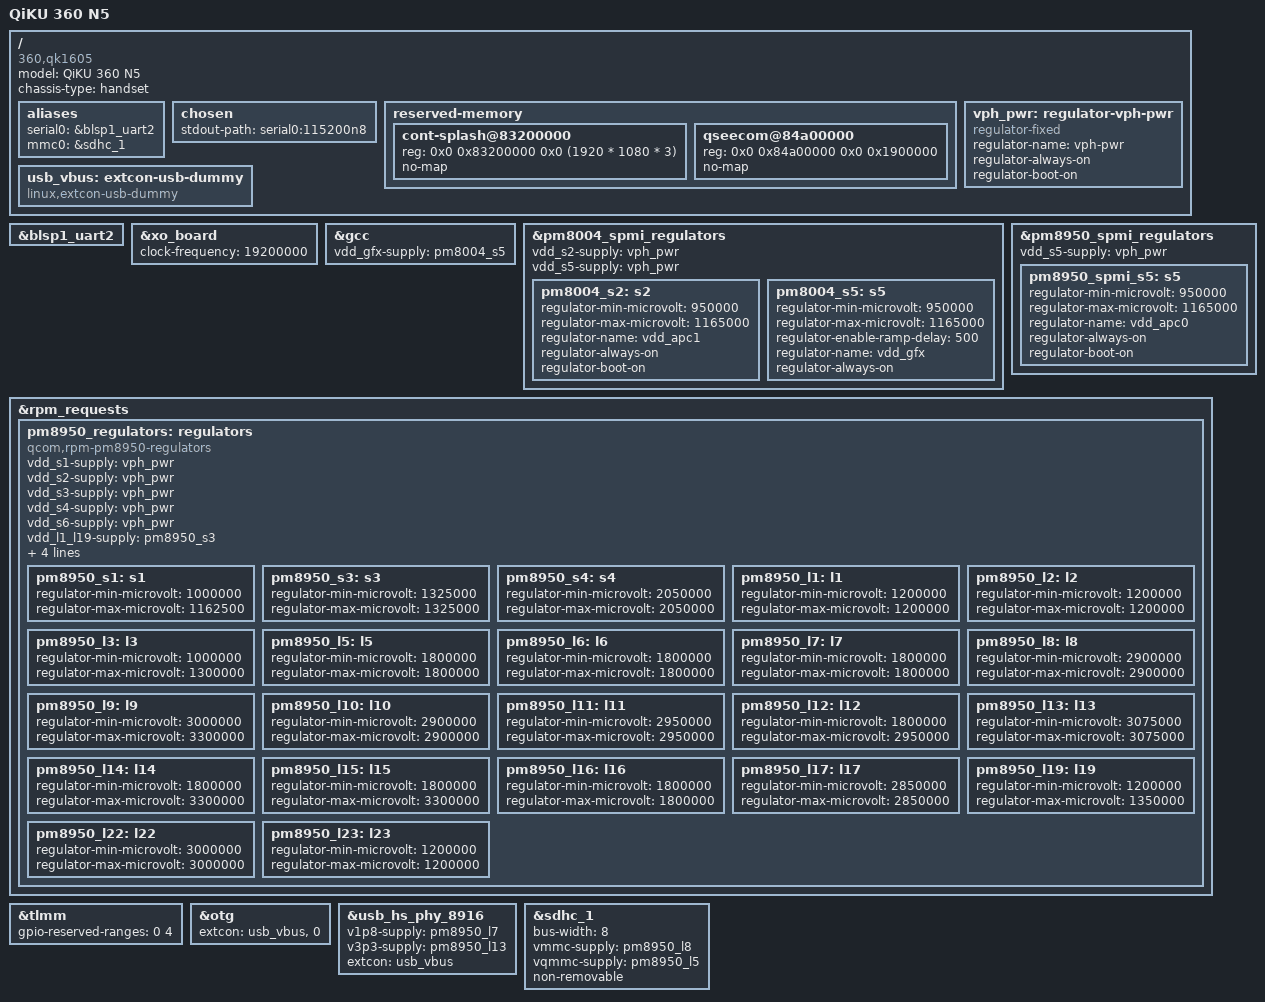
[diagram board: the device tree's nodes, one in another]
/dts-v1/;

#include "msm8976.dtsi"
#include "pm8004.dtsi"
#include "pm8950.dtsi"

/ {
	model = "QiKU 360 N5";
	compatible = "360,qk1605", "qcom,msm8976";
	chassis-type = "handset";

	aliases {
		serial0 = &blsp1_uart2;
		mmc0 = &sdhc_1; /* SDC1 eMMC slot */
	};

	chosen {
		stdout-path = "serial0:115200n8";
	};

	reserved-memory {
		cont-splash@83200000 {
			reg = <0x0 0x83200000 0x0 (1920 * 1080 * 3)>;
			no-map;
		};

		/delete-node/ ext-region@85b00000;
		/delete-node/ tz-apps@8dd00000;
		/delete-node/ memory@8da00000;
		qseecom@84a00000 {
			reg = <0x0 0x84a00000 0x0 0x1900000>;
			no-map;
		};
	};

	vph_pwr: regulator-vph-pwr {
		compatible = "regulator-fixed";
		regulator-name = "vph-pwr";
		regulator-always-on;
		regulator-boot-on;
	};

	usb_vbus: extcon-usb-dummy {
		compatible = "linux,extcon-usb-dummy";
	};
};

&blsp1_uart2 {
	status = "okay";
};

&xo_board {
	clock-frequency = <19200000>;
};

&gcc {
	vdd_gfx-supply = <&pm8004_s5>;
};

&pm8004_spmi_regulators {
	vdd_s2-supply = <&vph_pwr>;
	vdd_s5-supply = <&vph_pwr>;

	/* Cluster 1 supply */
	pm8004_s2: s2 {
		/* regulator-min-microvolt = <500000>; */
		/* Set .95V to prevent unstabilities until CPR for this SoC is done */
		regulator-min-microvolt = <950000>;
		regulator-max-microvolt = <1165000>;
		regulator-name = "vdd_apc1";
		/* Set always on until the CPU PLL is done */
		regulator-always-on;
		regulator-boot-on;
	};

	pm8004_s5: s5 {
		regulator-min-microvolt = <950000>;
		regulator-max-microvolt = <1165000>;
		regulator-enable-ramp-delay = <500>;
		regulator-name = "vdd_gfx";
		/* Hack this on until the gpu driver is ready for it */
		regulator-always-on;
	};
};

&pm8950_spmi_regulators {
	vdd_s5-supply = <&vph_pwr>;

	/* Cluster 0 supply */
	pm8950_spmi_s5: s5 {
		/* Set .95V to prevent unstabilities until CPR for this SoC is done */
		/* regulator-min-microvolt = <500000>; */
		regulator-min-microvolt = <950000>;
		regulator-max-microvolt = <1165000>;
		regulator-name = "vdd_apc0";
		/* Set always on until the CPU PLL is done */
		regulator-always-on;
		regulator-boot-on;
	};
};

&rpm_requests {
	pm8950_regulators: regulators {
		compatible = "qcom,rpm-pm8950-regulators";

		vdd_s1-supply = <&vph_pwr>;
		vdd_s2-supply = <&vph_pwr>;
		vdd_s3-supply = <&vph_pwr>;
		vdd_s4-supply = <&vph_pwr>;
		vdd_s6-supply = <&vph_pwr>;
		vdd_l1_l19-supply = <&pm8950_s3>;
		vdd_l2_l23-supply = <&pm8950_s3>;
		vdd_l3-supply = <&pm8950_s3>;
		vdd_l5_l6_l7_l16-supply = <&pm8950_s4>;
		vdd_l8_l11_l12_l17_l22-supply = <&vph_pwr>;

		pm8950_s1: s1 {
			regulator-min-microvolt = <1000000>;
			regulator-max-microvolt = <1162500>;
		};

		pm8950_s3: s3 {
			regulator-min-microvolt = <1325000>;
			regulator-max-microvolt = <1325000>;
		};

		pm8950_s4: s4 {
			regulator-min-microvolt = <2050000>;
			regulator-max-microvolt = <2050000>;
		};

		pm8950_l1: l1 {
			regulator-min-microvolt = <1200000>;
			regulator-max-microvolt = <1200000>;
		};

		pm8950_l2: l2 {
			regulator-min-microvolt = <1200000>;
			regulator-max-microvolt = <1200000>;
		};

		pm8950_l3: l3 {
			regulator-min-microvolt = <1000000>;
			regulator-max-microvolt = <1300000>;
		};

		pm8950_l5: l5 {
			regulator-min-microvolt = <1800000>;
			regulator-max-microvolt = <1800000>;
		};

		pm8950_l6: l6 {
			regulator-min-microvolt = <1800000>;
			regulator-max-microvolt = <1800000>;
		};

		pm8950_l7: l7 {
			regulator-min-microvolt = <1800000>;
			regulator-max-microvolt = <1800000>;
		};

		pm8950_l8: l8 {
			regulator-min-microvolt = <2900000>;
			regulator-max-microvolt = <2900000>;
		};

		pm8950_l9: l9 {
			regulator-min-microvolt = <3000000>;
			regulator-max-microvolt = <3300000>;
		};

		pm8950_l10: l10 {
			// regulator-min-microvolt = <3000000>;
			// regulator-max-microvolt = <3000000>;
			regulator-min-microvolt = <2900000>;
			regulator-max-microvolt = <2900000>;
		};

		pm8950_l11: l11 {
			regulator-min-microvolt = <2950000>;
			regulator-max-microvolt = <2950000>;
		};

		pm8950_l12: l12 {
			regulator-min-microvolt = <1800000>;
			regulator-max-microvolt = <2950000>;
		};

		pm8950_l13: l13 {
			regulator-min-microvolt = <3075000>;
			regulator-max-microvolt = <3075000>;
		};

		pm8950_l14: l14 {
			regulator-min-microvolt = <1800000>;
			regulator-max-microvolt = <3300000>;
		};

		pm8950_l15: l15 {
			regulator-min-microvolt = <1800000>;
			regulator-max-microvolt = <3300000>;
		};

		pm8950_l16: l16 {
			regulator-min-microvolt = <1800000>;
			regulator-max-microvolt = <1800000>;
		};

		pm8950_l17: l17 {
			regulator-min-microvolt = <2850000>;
			regulator-max-microvolt = <2850000>;
		};

		pm8950_l19: l19 {
			regulator-min-microvolt = <1200000>;
			regulator-max-microvolt = <1350000>;
		};

		pm8950_l22: l22 {
			regulator-min-microvolt = <3000000>;
			regulator-max-microvolt = <3000000>;
		};

		pm8950_l23: l23 {
			regulator-min-microvolt = <1200000>;
			regulator-max-microvolt = <1200000>;
		};
	};
};

&tlmm {
	gpio-reserved-ranges = <0 4>;
};

&otg {
	extcon = <&usb_vbus>, <0>;
	status = "okay";
};

&usb_hs_phy_8916 {
	v1p8-supply = <&pm8950_l7>;
	v3p3-supply = <&pm8950_l13>;
	extcon = <&usb_vbus>;
	status = "okay";
};

&sdhc_1 {
	bus-width = <8>;
	vmmc-supply = <&pm8950_l8>;
	vqmmc-supply = <&pm8950_l5>;
	non-removable;
	status = "okay";
};
